# f28004x_erad_global_registers_regs register map
Vendor: Texas Instruments
Peripheral module from a debugger description file (folder C2000).
Address unit: 16 bits
Registers are 16-bit, read-write, no defined reset value unless marked. A register's access mark holds for its fields unless they carry their own. Offsets are as the file gives them; lines under a group give offsets from that group; [hi:lo] are bit positions; {n}, {i} and the like mark numbered series; 'fields as' and 'values as' point back to an identical list; <NAME> marks a mode.

## ERAD_GLOBAL_REGISTERS — ERAD GLOBAL REGISTERS Registers
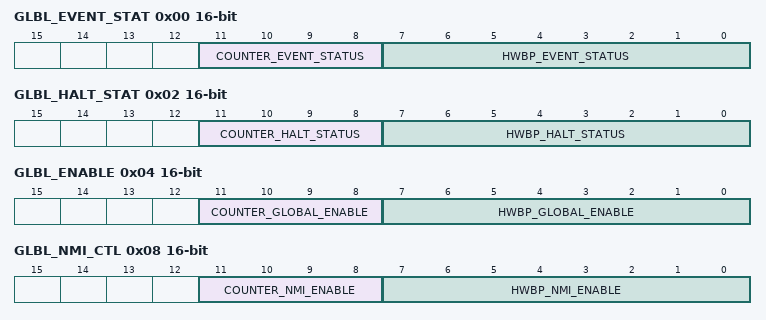
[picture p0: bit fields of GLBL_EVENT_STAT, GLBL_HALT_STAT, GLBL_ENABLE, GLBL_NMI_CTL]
0x00 GLBL_EVENT_STAT ro
  [11:8] COUNTER_EVENT_STATUS — Counter Module Event Status
  [7:0] HWBP_EVENT_STATUS — Bus Comparator Module Event Status
0x02 GLBL_HALT_STAT ro
  [11:8] COUNTER_HALT_STATUS — Counter Module Halt Status
  [7:0] HWBP_HALT_STATUS — Bus Comparator Module Halt Status
0x04 GLBL_ENABLE — GLBL_MODULE_ENABLE
  [11:8] COUNTER_GLOBAL_ENABLE — Counter Module Global Enable
  [7:0] HWBP_GLOBAL_ENABLE — Bus Comparator Module Global Enable
0x06 CTM_GLBL_RESET_1 access not given — CTM_GLBL_RESET
  [3:0] COUNTER_GLOBAL_RESET — Global Reset for the counters (access R=0/W)
0x08 GLBL_NMI_CTL — GLBL_NMI_CNTL
  [11:8] COUNTER_NMI_ENABLE — Reserved for future use
  [7:0] HWBP_NMI_ENABLE — Reserved for future use
0x0A GLBL_OWNER
  [1:0] OWNER — Global Ownership Bits
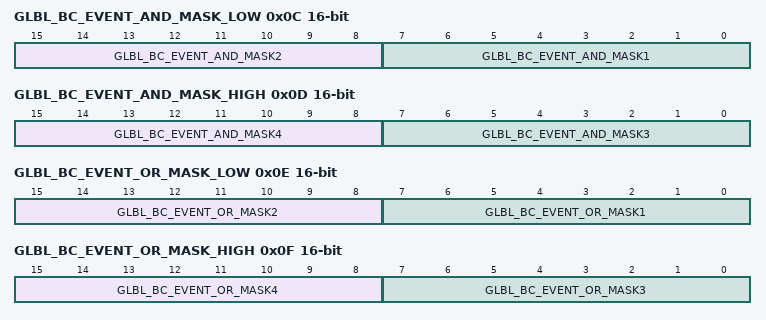
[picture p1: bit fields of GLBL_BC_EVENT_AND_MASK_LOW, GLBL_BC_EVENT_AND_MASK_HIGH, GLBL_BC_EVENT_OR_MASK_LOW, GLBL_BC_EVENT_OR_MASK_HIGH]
0x0C GLBL_BC_EVENT_AND_MASK_LOW
  [15:8] GLBL_BC_EVENT_AND_MASK2 — BusComparator AND Event Mask2
  [7:0] GLBL_BC_EVENT_AND_MASK1 — BusComparator AND Event Mask1
0x0D GLBL_BC_EVENT_AND_MASK_HIGH
  [15:8] GLBL_BC_EVENT_AND_MASK4 — BusComparator AND Event Mask4
  [7:0] GLBL_BC_EVENT_AND_MASK3 — BusComparator AND Event Mask3
0x0E GLBL_BC_EVENT_OR_MASK_LOW
  [15:8] GLBL_BC_EVENT_OR_MASK2 — BusComparator OR Event Mask2
  [7:0] GLBL_BC_EVENT_OR_MASK1 — BusComparator OR Event Mask1
0x0F GLBL_BC_EVENT_OR_MASK_HIGH
  [15:8] GLBL_BC_EVENT_OR_MASK4 — BusComparator OR Event Mask4
  [7:0] GLBL_BC_EVENT_OR_MASK3 — BusComparator OR Event Mask3
0x10 GLBL_AND_EVENT_INT_MASK
  [3:0] AND_MASK_RTOSINT_GEN — RTOSINT generation mask for global AND events
0x12 GLBL_OR_EVENT_INT_MASK
  [3:0] OR_MASK_RTOSINT_GEN — RTOSINT generation mask for global OR events
